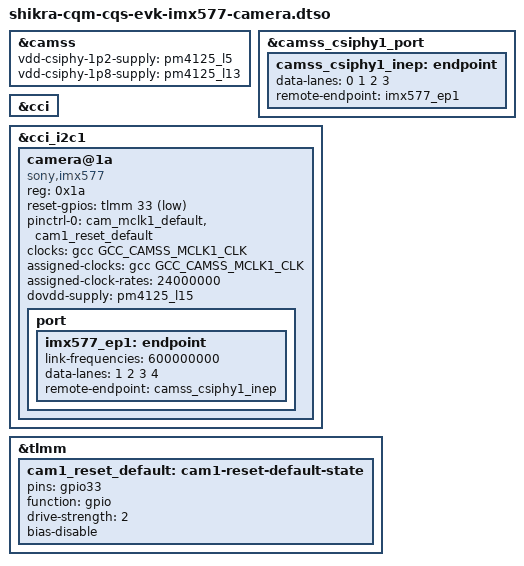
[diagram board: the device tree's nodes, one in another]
// SPDX-License-Identifier: BSD-3-Clause
/*
 * Copyright (c) Qualcomm Technologies, Inc. and/or its subsidiaries.
 */

/dts-v1/;
/plugin/;

#include <dt-bindings/clock/qcom,shikra-gcc.h>
#include <dt-bindings/gpio/gpio.h>

&camss {
	vdd-csiphy-1p2-supply = <&pm4125_l5>;
	vdd-csiphy-1p8-supply = <&pm4125_l13>;

	status = "okay";
};

&camss_csiphy1_port {
	camss_csiphy1_inep: endpoint {
		data-lanes = <0 1 2 3>;
		remote-endpoint = <&imx577_ep1>;
	};
};

&cci {
	status = "okay";
};

&cci_i2c1 {
	#address-cells = <1>;
	#size-cells = <0>;

	camera@1a {
		compatible = "sony,imx577";
		reg = <0x1a>;

		reset-gpios = <&tlmm 33 GPIO_ACTIVE_LOW>;
		pinctrl-0 = <&cam_mclk1_default &cam1_reset_default>;
		pinctrl-names = "default";

		clocks = <&gcc GCC_CAMSS_MCLK1_CLK>;
		assigned-clocks = <&gcc GCC_CAMSS_MCLK1_CLK>;
		assigned-clock-rates = <24000000>;

		/*
		 * avdd and dvdd are supplied by on-board regulators on the
		 * IMX577 module from the connector's 3.3 V rail; they are
		 * not SoC-controlled. dovdd (1.8 V) powers the carrier board
		 * level-shifter that translates CCI I2C and reset lines
		 * between the SoC and the connector.
		 */
		dovdd-supply = <&pm4125_l15>;

		port {
			imx577_ep1: endpoint {
				link-frequencies = /bits/ 64 <600000000>;
				data-lanes = <1 2 3 4>;
				remote-endpoint = <&camss_csiphy1_inep>;
			};
		};
	};
};

&tlmm {
	cam1_reset_default: cam1-reset-default-state {
		pins = "gpio33";
		function = "gpio";
		drive-strength = <2>;
		bias-disable;
	};
};
